# VIM_CFG0 register map
Vendor: Texas Instruments
Peripheral module from a debugger description file (folder am65x).
Registers are 32-bit, read-only, reset 0x0 unless marked. A register's access mark holds for its fields unless they carry their own. Offsets are as the file gives them; lines under a group give offsets from that group; [hi:lo] are bit positions; {n}, {i} and the like mark numbered series; 'fields as' and 'values as' point back to an identical list; <NAME> marks a mode.

## VIM_CFG0
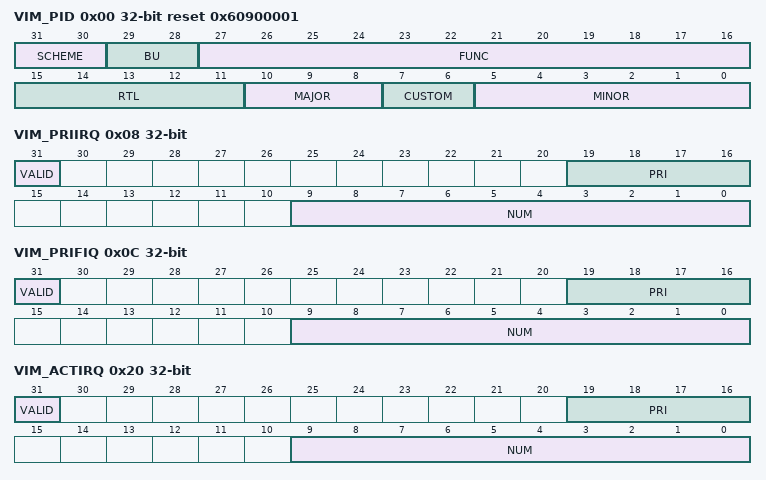
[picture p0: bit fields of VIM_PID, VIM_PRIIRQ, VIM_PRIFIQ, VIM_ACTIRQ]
0x00 VIM_PID reset 0x60900001 — The Revision Register contains the major and minor revisions for the module.
  [31:30] SCHEME
  [29:28] BU — Business Unit: 10 = Processors
  [27:16] FUNC — Module ID
  [15:11] RTL — RTL revision. Will vary depending on release.
  [10:8] MAJOR — Major revision
  [7:6] CUSTOM
  [5:0] MINOR — Minor revision
0x04 VIM_INFO reset 0x200 — The Info Register gives the configuration Inforrmation of this VIM.
  [10:0] INTERRUPTS — Total number of Interrupts
0x08 VIM_PRIIRQ — The Prioritized IRQ Register shows the number of the highest priority pending IRQ.
  [31] VALID — Indicates that the num field is valid. 0h = num field is invalid. 1h = num field is valid.
  [19:16] PRI — Priority of the highest priority pending IRQ. valid only if the valid flag is set.
  [9:0] NUM — Number of the highest priority pending IRQ. valid only if the valid flag is set.
0x0C VIM_PRIFIQ — The Prioritized FIQ Register shows the number of the highest priority pending FIQ.
  [31] VALID — Indicates that the num field is valid. 0h = num field is invalid. 1h = num field is valid.
  [19:16] PRI — Priority of the highest priority pending FIQ. valid only if the valid flag is set.
  [9:0] NUM — Number of the highest priority pending FIQ. valid only if the valid flag is set.
0x10 VIM_IRQGSTS — The IRQ Group Status Register indicates which groups have pending IRQ interrupts.
  [31:0] STS — Indicates that the num field is valid.
0x14 VIM_FIQGSTS — The FIQ Group Status Register indicates which groups have pending FIQ interrupts.
  [31:0] STS — Indicates that the num field is valid.
0x18 VIM_IRQVEC — The IRQ Vector Address Register contains the 32-bit address of the interrupt vector for the current pendind IRQ.
  [31:2] ADDR — Upper 30 bits of the 32-bit vector address. Only valid if the Prioritized IRQ Register valid flag is true.
0x1C VIM_FIQVEC — The FIQ Vector Address Register contains the 32-bit address of the interrupt vector for the current pendind FIQ.
  [31:2] ADDR — Upper 30 bits of the 32-bit vector address. Only valid if the Prioritized FIQ Register valid flag is true.
0x20 VIM_ACTIRQ — The Active IRQ Register shows the number of the currently active IRQ.
  [31] VALID — Indicates that the num field is valid. Set when the IRQ Vector Address Register is read and cleared whenever the IRQ Vector Address Register is written. 0h = num field is invalid. 1h = num field is valid.
  [19:16] PRI — Priority of the highest priority pending IRQ. valid only if the valid flag is set.
  [9:0] NUM — Number of the currently active IRQ. Loaded from teh Prioritized IRQ Register whenever the IRQ Vector Address is read. Valid only if the valid flag is set.
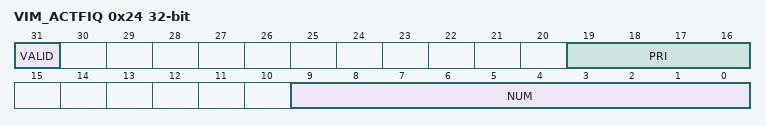
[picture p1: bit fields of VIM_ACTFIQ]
0x24 VIM_ACTFIQ — The Active FIQ Register shows the number of the currently active FIQ.
  [31] VALID — Indicates that the num field is valid. Set when the FIQ Vector Address Register is read and cleared whenever the FIQ Vector Address Register is written. 0h = num field is invalid. 1h = num field is valid.
  [19:16] PRI — Priority of the highest priority pending IRQ. valid only if the valid flag is set.
  [9:0] NUM — Number of the currently active FIQ. Loaded from teh Prioritized FIQ Register whenever the FIQ Vector Address is read. Valid only if the valid flag is set.
0x30 VIM_DEDVEC rw — The DED Vector Address contains a default vector address for when an uncorrectable error is detected for an active IRQ or FIQ.
  [31:2] ADDR — Upper 30 bits of the 32-bit vector address.
0x400 VIM_RAW_j access not given — Raw Status/Set Register for Group A Errors Offset = 400h + (j * 20h); where j = 0h to Fh
  [31:0] STS — This is the raw status/set for interrupts Group A (access RW1S)
0x404 VIM_STS_j access not given — Masked Status and Clear Register Offset = 404h + (j * 20h); where j = 0h to Fh
  [31:0] MSK — This is the masked status/clear for interrupts in Group A (access RW1C)
0x408 VIM_INTR_EN_SET_j access not given — Enable Set Register Offset = 408h + (j * 20h); where j = 0h to Fh
  [31:0] MSK — This is the mask enable set for interrupts in Group A (access RW1S)
0x40C VIM_INTR_EN_CLR_j access not given — Interrupt Enabled Clear register Offset = 40Ch + (j * 20h); where j = 0h to Fh
  [31:0] MSK — This is the mask enable clear for interrupts in Group A (access RW1C)
0x410 VIM_IRQSTS_j access not given — Masked IRQ Status and Clear Register Offset = 410h + (j * 20h); where j = 0h to Fh
  [31:0] MSK — This is the masked status/clear for interrupts in Group A mapped as IRQs (access RW1C)
0x414 VIM_FIQSTS_j access not given — Masked FIQ Status and Clear Register Offset = 414h + (j * 20h); where j = 0h to Fh
  [31:0] MSK — This is the masked status/clear for interrupts in Group A mapped as FIQs (access RW1C)
0x418 VIM_INTMAP_j rw — Maps interrupts to IRQ or FIQ Offset = 418h + (j * 20h); where j = 0h to Fh
  [31:0] MSK — This is interrupt map for interrupts in Group A. 0 - IRQ 1 - FIQ
0x41C VIM_INTTYPE_j rw — Indicates whether an interrupt is a pulse or level source Offset = 41Ch + (j * 20h); where j = 0h to Fh
  [31:0] MSK — This is interrupt type for interrupts in Group A. 0 - Level 1 - Pulse
0x1000 VIM_PRI_INT_j rw reset 0xF — This register contains the priority for Interrupt A Offset = 1000h + (j * 4h); where j = 0h to 1FFh
  [3:0] VAL — This is the priority for interrupt A. 0 - Highest ... 15 - Lowest (Default)
0x2000 VIM_VEC_INT_j rw — This register contains the vector for Interrupt A Offset = 2000h + (j * 4h); where j = 0h to 1FFh
  [31:2] VAL — This is the upper 30 bits of the 32-bits vector for interrupt A.
